# CY8C5267AXI_LP051 register map
File version: 0.1
Registers are 8-bit, read-write, no defined reset value unless marked. A register's access mark holds for its fields unless they carry their own. Offsets are from the block's base; [hi:lo] are bit positions; {n}, {i} and the like mark numbered series; 'fields as' and 'values as' point back to an identical list.

## UART_JY — UART
Base 0x00000000
0x4000642B RX_UART_JY_RX_ADDRESS1 — RX Address1 Register
0x4000643B RX_UART_JY_RX_ADDRESS2 — RX Address2 Register
0x4000644B RX_UART_JY_RX_DATA — RX Data Register
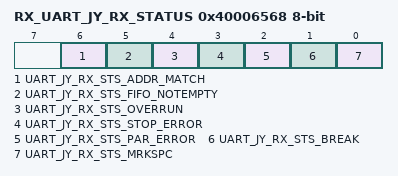
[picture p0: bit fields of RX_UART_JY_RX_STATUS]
0x40006568 RX_UART_JY_RX_STATUS — RX status register
  [6] UART_JY_RX_STS_ADDR_MATCH ro, [5] UART_JY_RX_STS_FIFO_NOTEMPTY ro, [4] UART_JY_RX_STS_OVERRUN ro, [3] UART_JY_RX_STS_STOP_ERROR ro, [2] UART_JY_RX_STS_PAR_ERROR ro, [1] UART_JY_RX_STS_BREAK ro, [0] UART_JY_RX_STS_MRKSPC ro

## UART_net — UART
Base 0x00000000
0x4000642D RX_UART_net_RX_ADDRESS1 — RX Address1 Register
0x4000643D RX_UART_net_RX_ADDRESS2 — RX Address2 Register
0x4000644D RX_UART_net_RX_DATA — RX Data Register
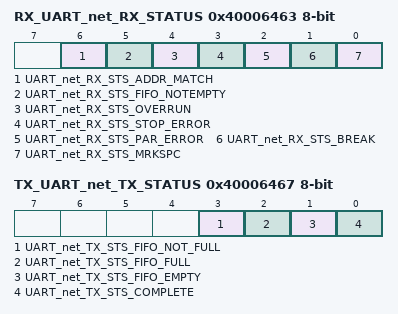
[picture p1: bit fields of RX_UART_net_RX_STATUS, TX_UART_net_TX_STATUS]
0x40006463 RX_UART_net_RX_STATUS — RX status register
  [6] UART_net_RX_STS_ADDR_MATCH ro, [5] UART_net_RX_STS_FIFO_NOTEMPTY ro, [4] UART_net_RX_STS_OVERRUN ro, [3] UART_net_RX_STS_STOP_ERROR ro, [2] UART_net_RX_STS_PAR_ERROR ro, [1] UART_net_RX_STS_BREAK ro, [0] UART_net_RX_STS_MRKSPC ro
0x40006467 TX_UART_net_TX_STATUS — TX status register
  [3] UART_net_TX_STS_FIFO_NOT_FULL ro, [2] UART_net_TX_STS_FIFO_FULL ro, [1] UART_net_TX_STS_FIFO_EMPTY ro, [0] UART_net_TX_STS_COMPLETE ro
0x40006544 TX_UART_net_TX_DATA — TX Data Register

## PWM_MOTOR_RIGHT
Base 0x00000000
0x40006429 PWM_MOTOR_RIGHT_COMPARE_1 16-bit — UDB.D0 - Assigned Compare1 Value
0x40006439 PWM_MOTOR_RIGHT_COMPARE_2 16-bit — UDB.D1 - Assigned Compare2 Value
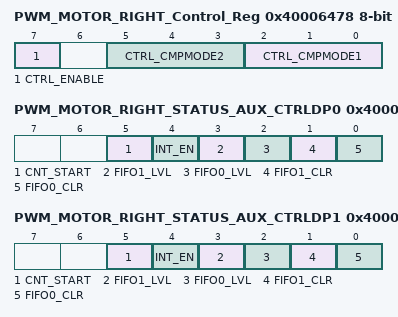
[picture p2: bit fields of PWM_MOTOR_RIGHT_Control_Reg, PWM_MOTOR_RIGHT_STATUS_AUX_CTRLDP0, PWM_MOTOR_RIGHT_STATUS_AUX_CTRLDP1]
0x40006478 PWM_MOTOR_RIGHT_Control_Reg — UDB Control Register - Assigned Control Register Value
  [7] CTRL_ENABLE — Enable the PWM
  [5:3] CTRL_CMPMODE2 — Compare mode 2
  [2:0] CTRL_CMPMODE1 — Compare mode 1
0x40006499 PWM_MOTOR_RIGHT_STATUS_AUX_CTRLDP0 — UDB Auxilliary Control Register
  [5] CNT_START — FIFO0 clear
    0=E_CNT_START0 (Disable counter); 1=E_CNT_START1 (Enable counter)
  [4] INT_EN
    0=E_INT_EN0 (Interrupt disabled); 1=E_INT_EN1 (Interrupt enabled)
  [3] FIFO1_LVL — FIFO level
    0=E_FIFO_LVL_0 (FIFO LVL: input mode: FIFO not full; output mode: FIFO not empty); 1=E_FIFO_LVL_1 (FIFO LVL: input mode: FIFO at least 1/2 empty; output mode: FIFO at least 1/2 full)
  [2] FIFO0_LVL — FIFO level
    values as FIFO1_LVL
  [1] FIFO1_CLR — FIFO1 clear
    0=E_FIFO_CLR_0 (Normal FIFO operation); 1=E_FIFO_CLR_1 (Clear FIFO state)
  [0] FIFO0_CLR — FIFO0 clear
    values as FIFO1_CLR
0x4000649A PWM_MOTOR_RIGHT_STATUS_AUX_CTRLDP1 — UDB Auxilliary Control Register
  fields as PWM_MOTOR_RIGHT_STATUS_AUX_CTRLDP0

## PWM_MOTOR_LEFT
Base 0x00000000
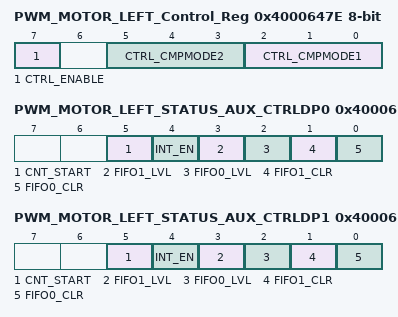
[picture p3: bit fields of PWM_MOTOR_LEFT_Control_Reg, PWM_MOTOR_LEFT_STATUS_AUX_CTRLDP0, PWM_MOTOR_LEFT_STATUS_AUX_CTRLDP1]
0x4000647E PWM_MOTOR_LEFT_Control_Reg — UDB Control Register - Assigned Control Register Value
  [7] CTRL_ENABLE — Enable the PWM
  [5:3] CTRL_CMPMODE2 — Compare mode 2
  [2:0] CTRL_CMPMODE1 — Compare mode 1
0x40006528 PWM_MOTOR_LEFT_COMPARE_1 16-bit — UDB.D0 - Assigned Compare1 Value
0x40006538 PWM_MOTOR_LEFT_COMPARE_2 16-bit — UDB.D1 - Assigned Compare2 Value
0x40006598 PWM_MOTOR_LEFT_STATUS_AUX_CTRLDP0 — UDB Auxilliary Control Register
  [5] CNT_START — FIFO0 clear
    0=E_CNT_START0 (Disable counter); 1=E_CNT_START1 (Enable counter)
  [4] INT_EN
    0=E_INT_EN0 (Interrupt disabled); 1=E_INT_EN1 (Interrupt enabled)
  [3] FIFO1_LVL — FIFO level
    0=E_FIFO_LVL_0 (FIFO LVL: input mode: FIFO not full; output mode: FIFO not empty); 1=E_FIFO_LVL_1 (FIFO LVL: input mode: FIFO at least 1/2 empty; output mode: FIFO at least 1/2 full)
  [2] FIFO0_LVL — FIFO level
    values as FIFO1_LVL
  [1] FIFO1_CLR — FIFO1 clear
    0=E_FIFO_CLR_0 (Normal FIFO operation); 1=E_FIFO_CLR_1 (Clear FIFO state)
  [0] FIFO0_CLR — FIFO0 clear
    values as FIFO1_CLR
0x40006599 PWM_MOTOR_LEFT_STATUS_AUX_CTRLDP1 — UDB Auxilliary Control Register
  fields as PWM_MOTOR_LEFT_STATUS_AUX_CTRLDP0

## ADC_SAR — SAR ADC
Base 0x00000000
0x40004614 SAR_TR0 — SAR trim register
{0x40005900+i} SAR_CSR{i} (i=0..6) — SAR status and control register {i}
0x40005B20 SAR_SW0 — SAR Analog Routing Register 0
{0x40005B20+i} SAR_SW{i} (i=2..4) — SAR Analog Routing Register {i}
0x40005B26 SAR_SW6 — SAR Analog Routing Register 6
0x40005B27 SAR_CLK — SAR Clock Selection Register
0x40005BA0 SAR_WRK 16-bit — SAR working register
